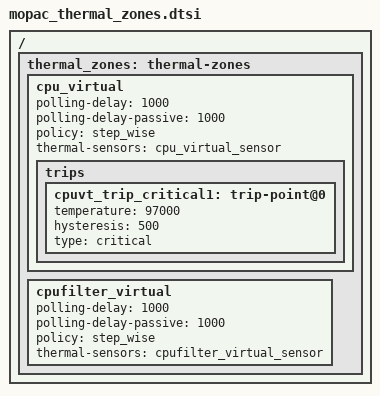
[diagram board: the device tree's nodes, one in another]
/*
 * arch/arm64/boot/dts/mediatek/brownie_thermal_zones.dtsi
 *
 * Copyright (C) 2019-2020 Amazon, Inc. All rights reserved.
 *
 * This program is free software; you can redistribute it and/or modify
 * it under the terms of the GNU General Public License as published by
 * the Free Software Foundation; either version 2 of the License, or
 * (at your option) any later version.
 *
 * This program is distributed in the hope that it will be useful, but WITHOUT
 * ANY WARRANTY; without even the implied warranty of MERCHANTABILITY or
 * FITNESS FOR A PARTICULAR PURPOSE.  See the GNU General Public License for
 * more details.
 *
*/

/ {

	thermal_zones: thermal-zones {


		cpu_virtual: cpu_virtual {
			polling-delay = <1000>;
			polling-delay-passive = <1000>;
			policy = "step_wise";
			thermal-sensors = <&cpu_virtual_sensor>;

			trips {
				cpuvt_trip_critical1: trip-point@0 {
					temperature = <97000>;
					hysteresis = <500>;
					type = "critical";
				};
			};
		};

		cpufilter_virtual: cpufilter_virtual {
			polling-delay = <1000>;
			polling-delay-passive = <1000>;
			policy = "step_wise";
			thermal-sensors = <&cpufilter_virtual_sensor>;
		};
	};
};
